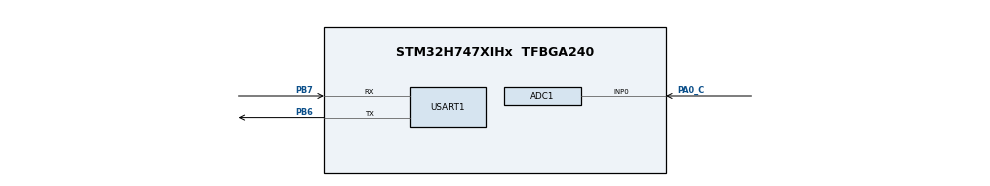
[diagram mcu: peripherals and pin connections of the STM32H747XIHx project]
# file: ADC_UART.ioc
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ADC1.Channel-0\#ChannelRegularConversion=ADC_CHANNEL_0
ADC1.NbrOfConversionFlag=1
ADC1.OffsetNumber-0\#ChannelRegularConversion=ADC_OFFSET_NONE
ADC1.OffsetSignedSaturation-0\#ChannelRegularConversion=DISABLE
ADC1.Rank-0\#ChannelRegularConversion=1
ADC1.SamplingTime-0\#ChannelRegularConversion=ADC_SAMPLETIME_1CYCLE_5
ADC1.master=1
CortexM4.IPs=BDMA,CORTEX_M4\:I,DEBUG,DMA,FATFS_M4\:I,FREERTOS_M4\:I,GPIO,IWDG2\:I,MDMA,NVIC2\:I,OPENAMP_M4\:I,PDM2PCM_M4\:I,PWR,RCC,RESMGR_UTILITY,SYS_M4\:I,USB_DEVICE_M4\:I,USB_HOST_M4\:I,VREFBUF,WWDG2\:I
CortexM7.IPs=BDMA\:I,CORTEX_M7\:I,DEBUG\:I,DMA\:I,FATFS_M7\:I,FREERTOS_M7\:I,GPIO\:I,IWDG1\:I,MDMA\:I,NVIC1\:I,OPENAMP_M7\:I,PDM2PCM_M7\:I,PWR\:I,RCC\:I,RESMGR_UTILITY\:I,SYS\:I,USB_DEVICE_M7\:I,USB_HOST_M7\:I,VREFBUF\:I,WWDG1\:I,ADC1\:I,USART1\:I
Mcu.Family=STM32H7
Mcu.Name=STM32H747XIHx
Mcu.Package=TFBGA240
NVIC1.ADC_IRQn=true\:5\:0\:true\:false\:true\:true\:true\:true
NVIC1.PriorityGroup=NVIC_PRIORITYGROUP_4
NVIC2.PriorityGroup=NVIC_PRIORITYGROUP_4
PA0_C.PinAttribute=CortexM7
PA0_C.Signal=ADCx_INP0
PB6.Mode=Asynchronous
PB6.PinAttribute=CortexM7
PB6.Signal=USART1_TX
PB7.Mode=Asynchronous
PB7.PinAttribute=CortexM7
PB7.Signal=USART1_RX
PH0-OSC_IN\ (PH0).Mode=HSE-External-Oscillator
PH0-OSC_IN\ (PH0).PinAttribute=Free
PH0-OSC_IN\ (PH0).Signal=RCC_OSC_IN
PH1-OSC_OUT\ (PH1).Mode=HSE-External-Oscillator
PH1-OSC_OUT\ (PH1).PinAttribute=Free
PH1-OSC_OUT\ (PH1).Signal=RCC_OSC_OUT
ProjectManager.HeapSize=M4-0x200,M7-0x200
ProjectManager.StackSize=M4-0x400,M7-0x400
ProjectManager.TargetToolchain=STM32CubeIDE
RCC.ADCFreq_Value=75000000
RCC.APB1Freq_Value=75000000
RCC.APB2Freq_Value=37500000
RCC.APB3Freq_Value=75000000
RCC.APB4Freq_Value=75000000
RCC.CortexFreq_Value=75000000
RCC.D2PPRE2=RCC_APB2_DIV2
RCC.DIVM1=2
RCC.DIVM2=2
RCC.DIVN1=12
RCC.DIVN2=12
RCC.HCLKFreq_Value=75000000
RCC.PLL2FRACN=0
RCC.PLLFRACN=0
RCC.PLLSourceVirtual=RCC_PLLSOURCE_HSE
RCC.SYSCLKFreq_VALUE=75000000
RCC.SYSCLKSource=RCC_SYSCLKSOURCE_PLLCLK
RCC.USBFreq_Value=75000000
SH.ADCx_INP0.0=ADC1_INP0,IN0-Single-Ended
SYS.userName=SYS_M7
USART1.VirtualMode-Asynchronous=VM_ASYNC
VP_SYS_M4_VS_Systick.Mode=SysTick
board=custom

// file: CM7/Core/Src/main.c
/* USER CODE BEGIN Header */
/**
  ******************************************************************************
  * @file           : main.c
  * @brief          : Main program body
  ******************************************************************************
  * @attention
  *
  * Copyright (c) 2024 STMicroelectronics.
  * All rights reserved.
  *
  * This software is licensed under terms that can be found in the LICENSE file
  * in the root directory of this software component.
  * If no LICENSE file comes with this software, it is provided AS-IS.
  *
  ******************************************************************************
  */
/* USER CODE END Header */
#include "main.h"

/* USER CODE BEGIN Includes */
#include <stdlib.h>
#include <stdio.h>
#include <string.h>
/* USER CODE END Includes */

/* USER CODE BEGIN PD */

#ifndef HSEM_ID_0
#define HSEM_ID_0 (0U) /* HW semaphore 0*/
#endif

/* USER CODE END PD */

ADC_HandleTypeDef hadc1;

UART_HandleTypeDef huart1;

/* USER CODE BEGIN PV */
char txBuf[50];
uint32_t adc_result;
char adc_valid;
/* USER CODE END PV */

void SystemClock_Config(void);
static void MX_GPIO_Init(void);
static void MX_ADC1_Init(void);
static void MX_USART1_UART_Init(void);

/* USER CODE BEGIN 0 */
void HAL_ADC_ConvCpltCallback(ADC_HandleTypeDef *hadc){
	adc_valid = 1;
	adc_result = HAL_ADC_GetValue(&hadc1);
}
/* USER CODE END 0 */

int main(void)
{
/* USER CODE BEGIN Boot_Mode_Sequence_0 */
  int32_t timeout;
/* USER CODE END Boot_Mode_Sequence_0 */

/* USER CODE BEGIN Boot_Mode_Sequence_1 */
  /* Wait until CPU2 boots and enters in stop mode or timeout*/
  timeout = 0xFFFF;
  while((__HAL_RCC_GET_FLAG(RCC_FLAG_D2CKRDY) != RESET) && (timeout-- > 0));
  if ( timeout < 0 )
  {
  Error_Handler();
  }
/* USER CODE END Boot_Mode_Sequence_1 */
  /* MCU Configuration--------------------------------------------------------*/

  /* Reset of all peripherals, Initializes the Flash interface and the Systick. */
  HAL_Init();

  /* Configure the system clock */
  SystemClock_Config();
/* USER CODE BEGIN Boot_Mode_Sequence_2 */
/* When system initialization is finished, Cortex-M7 will release Cortex-M4 by means of
HSEM notification */
/*HW semaphore Clock enable*/
__HAL_RCC_HSEM_CLK_ENABLE();
/*Take HSEM */
HAL_HSEM_FastTake(HSEM_ID_0);
/*Release HSEM in order to notify the CPU2(CM4)*/
HAL_HSEM_Release(HSEM_ID_0,0);
/* wait until CPU2 wakes up from stop mode */
timeout = 0xFFFF;
while((__HAL_RCC_GET_FLAG(RCC_FLAG_D2CKRDY) == RESET) && (timeout-- > 0));
if ( timeout < 0 )
{
Error_Handler();
}
/* USER CODE END Boot_Mode_Sequence_2 */

  /* Initialize all configured peripherals */
  MX_GPIO_Init();
  MX_ADC1_Init();
  MX_USART1_UART_Init();

  /* Infinite loop */
  while (1)
  {

    /* USER CODE BEGIN 3 */
	  if(adc_valid == 1){
		  sprintf(txBuf, "ADC: %d\r\n", (int)adc_result);
		  HAL_UART_Transmit(&huart1, (uint8_t *)txBuf, strlen(txBuf), HAL_MAX_DELAY);
		  adc_valid = 0;
		  HAL_ADC_Start_IT(&hadc1);
	  }
	  HAL_Delay(100);
  }
  /* USER CODE END 3 */
}

void SystemClock_Config(void)
{
  RCC_OscInitTypeDef RCC_OscInitStruct = {0};
  RCC_ClkInitTypeDef RCC_ClkInitStruct = {0};

  /** Supply configuration update enable
  */
  HAL_PWREx_ConfigSupply(PWR_DIRECT_SMPS_SUPPLY);

  /** Configure the main internal regulator output voltage
  */
  __HAL_PWR_VOLTAGESCALING_CONFIG(PWR_REGULATOR_VOLTAGE_SCALE3);

  while(!__HAL_PWR_GET_FLAG(PWR_FLAG_VOSRDY)) {}

  /** Initializes the RCC Oscillators according to the specified parameters
  * in the RCC_OscInitTypeDef structure.
  */
  RCC_OscInitStruct.OscillatorType = RCC_OSCILLATORTYPE_HSE;
  RCC_OscInitStruct.HSEState = RCC_HSE_ON;
  RCC_OscInitStruct.PLL.PLLState = RCC_PLL_ON;
  RCC_OscInitStruct.PLL.PLLSource = RCC_PLLSOURCE_HSE;
  RCC_OscInitStruct.PLL.PLLM = 2;
  RCC_OscInitStruct.PLL.PLLN = 12;
  RCC_OscInitStruct.PLL.PLLP = 2;
  RCC_OscInitStruct.PLL.PLLQ = 2;
  RCC_OscInitStruct.PLL.PLLR = 2;
  RCC_OscInitStruct.PLL.PLLRGE = RCC_PLL1VCIRANGE_3;
  RCC_OscInitStruct.PLL.PLLVCOSEL = RCC_PLL1VCOMEDIUM;
  RCC_OscInitStruct.PLL.PLLFRACN = 0;
  if (HAL_RCC_OscConfig(&RCC_OscInitStruct) != HAL_OK)
  {
    Error_Handler();
  }

  /** Initializes the CPU, AHB and APB buses clocks
  */
  RCC_ClkInitStruct.ClockType = RCC_CLOCKTYPE_HCLK|RCC_CLOCKTYPE_SYSCLK
                              |RCC_CLOCKTYPE_PCLK1|RCC_CLOCKTYPE_PCLK2
                              |RCC_CLOCKTYPE_D3PCLK1|RCC_CLOCKTYPE_D1PCLK1;
  RCC_ClkInitStruct.SYSCLKSource = RCC_SYSCLKSOURCE_PLLCLK;
  RCC_ClkInitStruct.SYSCLKDivider = RCC_SYSCLK_DIV1;
  RCC_ClkInitStruct.AHBCLKDivider = RCC_HCLK_DIV1;
  RCC_ClkInitStruct.APB3CLKDivider = RCC_APB3_DIV1;
  RCC_ClkInitStruct.APB1CLKDivider = RCC_APB1_DIV1;
  RCC_ClkInitStruct.APB2CLKDivider = RCC_APB2_DIV2;
  RCC_ClkInitStruct.APB4CLKDivider = RCC_APB4_DIV1;

  if (HAL_RCC_ClockConfig(&RCC_ClkInitStruct, FLASH_LATENCY_1) != HAL_OK)
  {
    Error_Handler();
  }
}

static void MX_ADC1_Init(void)
{

  ADC_MultiModeTypeDef multimode = {0};
  ADC_ChannelConfTypeDef sConfig = {0};

  /** Common config
  */
  hadc1.Instance = ADC1;
  hadc1.Init.ClockPrescaler = ADC_CLOCK_ASYNC_DIV2;
  hadc1.Init.Resolution = ADC_RESOLUTION_16B;
  hadc1.Init.ScanConvMode = ADC_SCAN_DISABLE;
  hadc1.Init.EOCSelection = ADC_EOC_SINGLE_CONV;
  hadc1.Init.LowPowerAutoWait = DISABLE;
  hadc1.Init.ContinuousConvMode = DISABLE;
  hadc1.Init.NbrOfConversion = 1;
  hadc1.Init.DiscontinuousConvMode = DISABLE;
  hadc1.Init.ExternalTrigConv = ADC_SOFTWARE_START;
  hadc1.Init.ExternalTrigConvEdge = ADC_EXTERNALTRIGCONVEDGE_NONE;
  hadc1.Init.ConversionDataManagement = ADC_CONVERSIONDATA_DR;
  hadc1.Init.Overrun = ADC_OVR_DATA_PRESERVED;
  hadc1.Init.LeftBitShift = ADC_LEFTBITSHIFT_NONE;
  hadc1.Init.OversamplingMode = DISABLE;
  if (HAL_ADC_Init(&hadc1) != HAL_OK)
  {
    Error_Handler();
  }

  /** Configure the ADC multi-mode
  */
  multimode.Mode = ADC_MODE_INDEPENDENT;
  if (HAL_ADCEx_MultiModeConfigChannel(&hadc1, &multimode) != HAL_OK)
  {
    Error_Handler();
  }

  /** Configure Regular Channel
  */
  sConfig.Channel = ADC_CHANNEL_0;
  sConfig.Rank = ADC_REGULAR_RANK_1;
  sConfig.SamplingTime = ADC_SAMPLETIME_1CYCLE_5;
  sConfig.SingleDiff = ADC_SINGLE_ENDED;
  sConfig.OffsetNumber = ADC_OFFSET_NONE;
  sConfig.Offset = 0;
  sConfig.OffsetSignedSaturation = DISABLE;
  if (HAL_ADC_ConfigChannel(&hadc1, &sConfig) != HAL_OK)
  {
    Error_Handler();
  }

}

static void MX_USART1_UART_Init(void)
{

  huart1.Instance = USART1;
  huart1.Init.BaudRate = 115200;
  huart1.Init.WordLength = UART_WORDLENGTH_8B;
  huart1.Init.StopBits = UART_STOPBITS_1;
  huart1.Init.Parity = UART_PARITY_NONE;
  huart1.Init.Mode = UART_MODE_TX_RX;
  huart1.Init.HwFlowCtl = UART_HWCONTROL_NONE;
  huart1.Init.OverSampling = UART_OVERSAMPLING_16;
  huart1.Init.OneBitSampling = UART_ONE_BIT_SAMPLE_DISABLE;
  huart1.Init.ClockPrescaler = UART_PRESCALER_DIV1;
  huart1.AdvancedInit.AdvFeatureInit = UART_ADVFEATURE_NO_INIT;
  if (HAL_UART_Init(&huart1) != HAL_OK)
  {
    Error_Handler();
  }
  if (HAL_UARTEx_SetTxFifoThreshold(&huart1, UART_TXFIFO_THRESHOLD_1_8) != HAL_OK)
  {
    Error_Handler();
  }
  if (HAL_UARTEx_SetRxFifoThreshold(&huart1, UART_RXFIFO_THRESHOLD_1_8) != HAL_OK)
  {
    Error_Handler();
  }
  if (HAL_UARTEx_DisableFifoMode(&huart1) != HAL_OK)
  {
    Error_Handler();
  }

}

static void MX_GPIO_Init(void)
{

  /* GPIO Ports Clock Enable */
  __HAL_RCC_GPIOB_CLK_ENABLE();
  __HAL_RCC_GPIOA_CLK_ENABLE();

}

void Error_Handler(void)
{
  __disable_irq();
  while (1)
  {
  }
}
